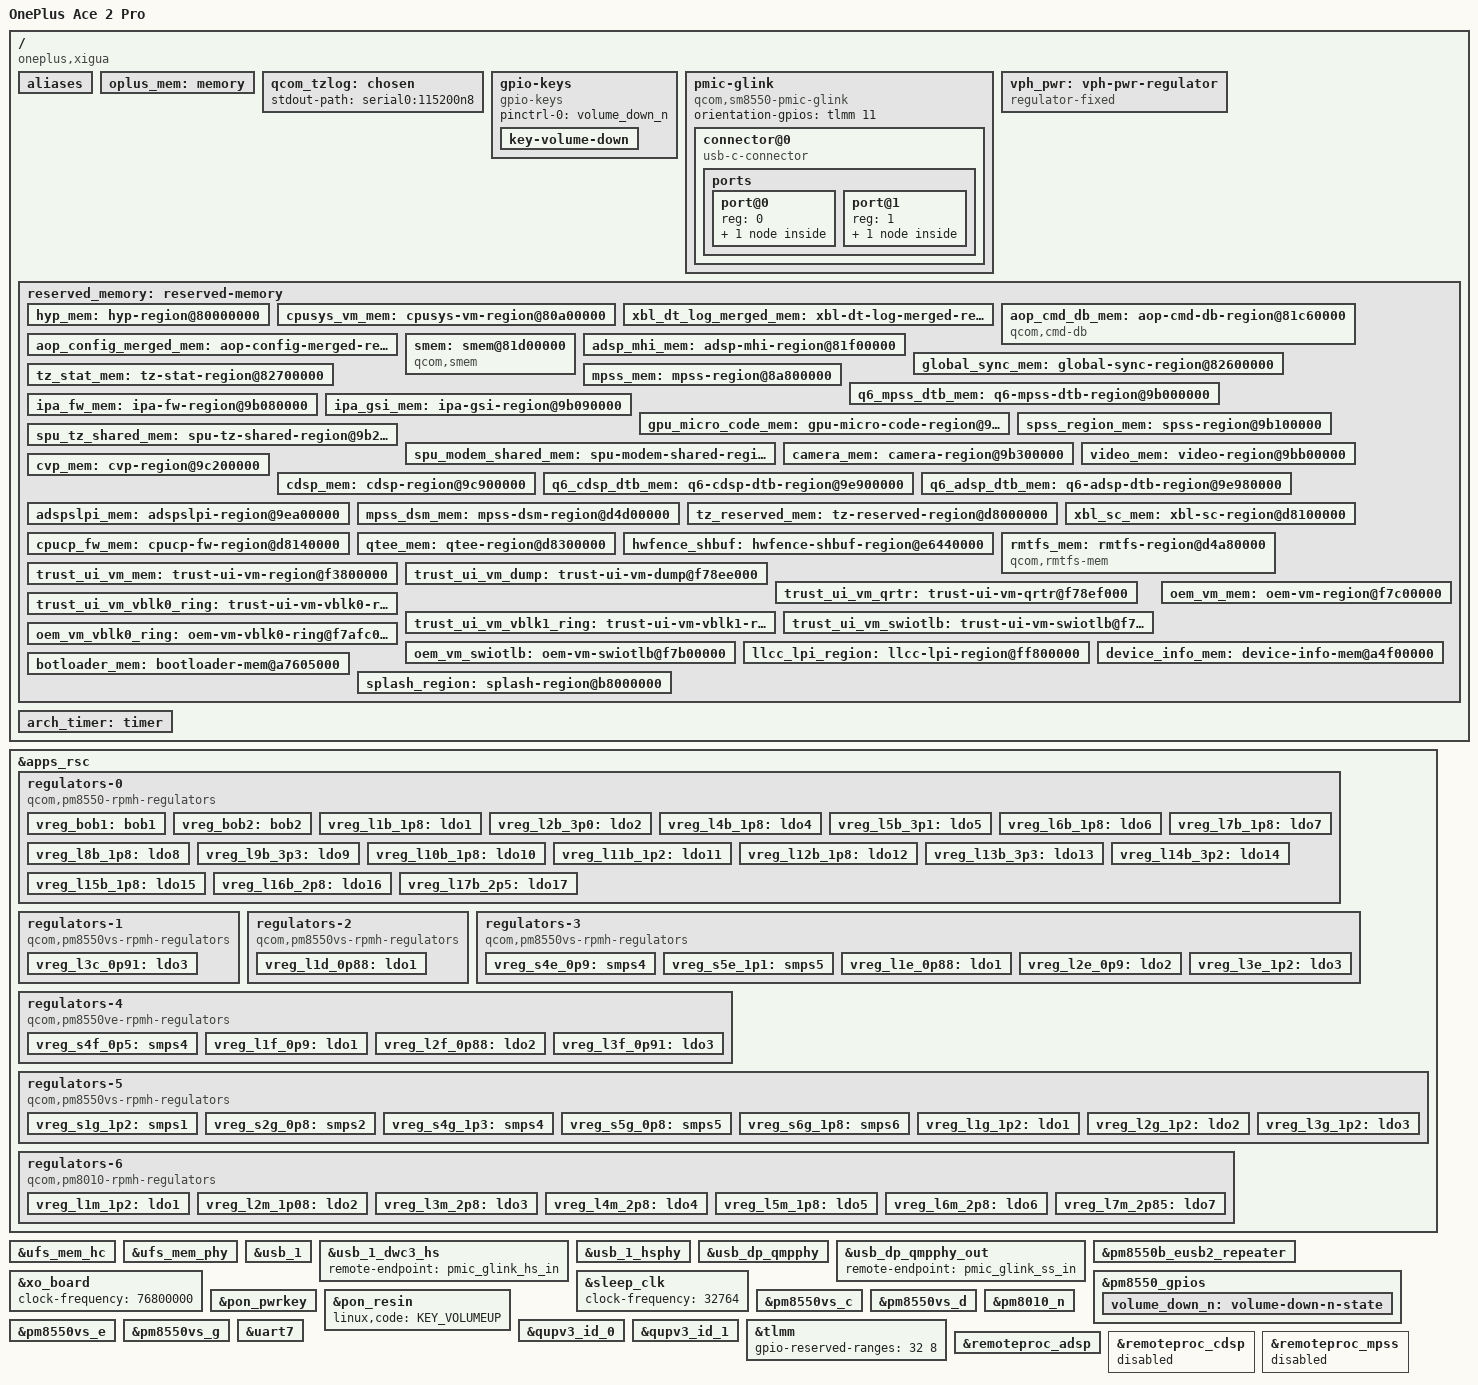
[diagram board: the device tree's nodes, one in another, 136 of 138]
// SPDX-License-Identifier: BSD-3-Clause
/*
 * OnePlus Ace 2 Pro (PJA110 / "xigua") - mainline bring-up, stage 0
 *
 * Goal of this revision: boot to a serial/USB shell. Deliberately minimal:
 * SoC + memory map + storage + USB + PMIC. No display, no touch, no modem.
 *
 * Sources for every board-specific value below:
 *   - reserved-memory : vendor_boot-A14.img (V14.0.0.701 / Android 14 base DTB)
 *   - regulators      : vendor base DTB, cross-checked against the sibling
 *                       OnePlus Ace 3 port (same PMIC set)
 *   - UFS / USB GPIOs : OnePlus sm8550 family layout (same as Ace 3)
 *   - RAM map         : see sm8550-oneplus-xigua_*.dts variants
 *
 * NOTE: the vendor base DTB keeps the factory memory map in an internal
 * "Kalama MTP,xigua" layout. We delete upstream's reserved-memory wholesale and
 * re-declare exactly what this device has (see docs/resmem-worklist.md).
 */

/dts-v1/;

#include <dt-bindings/arm/qcom,ids.h>
#include <dt-bindings/firmware/qcom,scm.h>
#include <dt-bindings/gpio/gpio.h>
#include <dt-bindings/input/input.h>
#include <dt-bindings/interrupt-controller/arm-gic.h>
#include <dt-bindings/leds/common.h>
#include <dt-bindings/regulator/qcom,rpmh-regulator.h>
#include <dt-bindings/sound/qcom,q6afe.h>
#include <dt-bindings/sound/qcom,q6asm.h>
#include <dt-bindings/sound/qcom,q6dsp-lpass-ports.h>
#include "sm8550.dtsi"
#include "pm8010.dtsi"
#include "pm8550.dtsi"
#include "pm8550b.dtsi"
#define PMK8550VE_SID 5
#include "pm8550ve.dtsi"
#include "pm8550vs.dtsi"
#include "pmk8550.dtsi"
#include "pmr735d_a.dtsi"

/*
 * Start from a clean slate: upstream sm8550.dtsi declares 47 reservations for
 * the reference boards. This device has 40, and 7 of the upstream ones do not
 * exist here at all. Re-declaring the node avoids a long, error-prone
 * /delete-node/ list (this is also what the Ace 3 port does).
 */
/delete-node/ &reserved_memory;

/ {
	model = "OnePlus Ace 2 Pro";
	compatible = "oneplus,xigua", "qcom,sm8550";
	chassis-type = "handset";

	/* same silicon variants as the rest of the OnePlus sm8550 family */
	qcom,msm-id = <0x207 0x20000 0x207 0x10000 0x218 0x20000 0x218 0x10000>;
	qcom,board-id = <0x10008 0>;

	aliases {
		serial0 = &uart7;
		serial1 = &uart14;
	};

	/*
	 * RAM map.
	 *
	 * Upstream sm8550.dtsi declares "memory@a0000000" with a zero size and
	 * expects the bootloader to fill it in; the vendor firmware does the same
	 * with its own /memory node. We cannot recover this device's real map from
	 * the firmware images (xbl/xbl_config/abl contain no size table, and the
	 * vendor base DTB leaves reg empty), so the map is supplied explicitly by
	 * the size specific variants, e.g. sm8550-oneplus-xigua-16G.dts.
	 *
	 * The base file keeps a single conservative window that is guaranteed to
	 * sit inside real RAM and outside every reserved region, so the base DTB
	 * boots (with less RAM) even without a variant.
	 */
	oplus_mem: memory {
		device_type = "memory";
		ddr_device_type = <0x08>;
		/* 0x80000000..0x8a800000: after hyp/cpusys/xbl, before mpss.
		 * Overridden by the size-specific variant. */
		reg = <0x00 0x80000000 0x00 0xa800000>;
	};

	/*
	 * ABL workaround -- see "ABL / DTBO" in docs/dts-build.md.
	 *
	 * This device's ABL refuses to apply a DTBO unless the *base* DTB contains
	 * a label named "qcom_tzlog" and a timer node labelled "arch_timer".
	 * Without them it drops to the bootloader menu.
	 *
	 * If we boot with `fastboot erase dtbo` (no overlay to apply) this is not
	 * needed -- but it costs nothing and makes an in-place DTBO setup work too,
	 * so we carry it. Upstream rejected putting this in sm8550.dtsi (it is an
	 * ABL quirk, not an SoC property), so it lives in the board DTS.
	 */
	qcom_tzlog: chosen {
		#address-cells = <2>;
		#size-cells = <2>;
		ranges;
		/* bring-up console: the vendor firmware disables it (console=ttynull) */
		stdout-path = "serial0:115200n8";
	};

	gpio-keys {
		compatible = "gpio-keys";
		pinctrl-names = "default";
		pinctrl-0 = <&volume_down_n>;

		key-volume-down {
			label = "Volume Down";
			linux,code = <KEY_VOLUMEDOWN>;
			gpios = <&pm8550_gpios 6 GPIO_ACTIVE_LOW>;
			debounce-interval = <15>;
			linux,can-disable;
			wakeup-source;
		};
	};

	pmic-glink {
		compatible = "qcom,sm8550-pmic-glink", "qcom,pmic-glink";
		#address-cells = <1>;
		#size-cells = <0>;
		orientation-gpios = <&tlmm 11 GPIO_ACTIVE_HIGH>;

		connector@0 {
			compatible = "usb-c-connector";
			reg = <0>;
			power-role = "dual";
			data-role = "dual";

			ports {
				#address-cells = <1>;
				#size-cells = <0>;

				port@0 {
					reg = <0>;

					pmic_glink_hs_in: endpoint {
						remote-endpoint = <&usb_1_dwc3_hs>;
					};
				};

				port@1 {
					reg = <1>;

					pmic_glink_ss_in: endpoint {
						remote-endpoint = <&usb_dp_qmpphy_out>;
					};
				};
			};
		};
	};

	vph_pwr: vph-pwr-regulator {
		compatible = "regulator-fixed";
		regulator-name = "vph_pwr";
		regulator-min-microvolt = <3700000>;
		regulator-max-microvolt = <3700000>;

		regulator-always-on;
		regulator-boot-on;
	};

	/*
	 * Memory map taken verbatim from the vendor base DTB (see
	 * docs/resmem-worklist.md for how each entry was derived).
	 */
	reserved_memory: reserved-memory {
		#address-cells = <2>;
		#size-cells = <2>;
		ranges;

		/* upstream calls this hyp_mem; the vendor node is gunyah_hyp_region */
		hyp_mem: hyp-region@80000000 {
			no-map;
			reg = <0x00 0x80000000 0x00 0xa00000>;
		};

		cpusys_vm_mem: cpusys-vm-region@80a00000 {
			no-map;
			reg = <0x00 0x80a00000 0x00 0x400000>;
		};

		/* NOTE: xigua has no hyp_tags_mem / hyp_tags_reserved_mem (upstream does) */

		/* merged xbl_dt_log, xbl_ramdump, aop_image */
		xbl_dt_log_merged_mem: xbl-dt-log-merged-region@81a00000 {
			no-map;
			reg = <0x00 0x81a00000 0x00 0x260000>;
		};

		aop_cmd_db_mem: aop-cmd-db-region@81c60000 {
			compatible = "qcom,cmd-db";
			no-map;
			reg = <0x00 0x81c60000 0x00 0x20000>;
		};

		/* merged aop_config, tme_crash_dump, tme_log, uefi_log */
		aop_config_merged_mem: aop-config-merged-region@81c80000 {
			no-map;
			reg = <0x00 0x81c80000 0x00 0x74000>;
		};

		smem: smem@81d00000 {
			compatible = "qcom,smem";
			no-map;
			reg = <0x00 0x81d00000 0x00 0x200000>;
			hwlocks = <&tcsr_mutex 3>;
		};

		adsp_mhi_mem: adsp-mhi-region@81f00000 {
			no-map;
			reg = <0x00 0x81f00000 0x00 0x20000>;
		};

		global_sync_mem: global-sync-region@82600000 {
			no-map;
			reg = <0x00 0x82600000 0x00 0x100000>;
		};

		tz_stat_mem: tz-stat-region@82700000 {
			no-map;
			reg = <0x00 0x82700000 0x00 0x100000>;
		};

		/* NOTE: xigua has no cdsp_secure_heap_mem (upstream has 70 MiB here) */

		mpss_mem: mpss-region@8a800000 {
			no-map;
			reg = <0x00 0x8a800000 0x00 0x10800000>;
		};

		q6_mpss_dtb_mem: q6-mpss-dtb-region@9b000000 {
			no-map;
			reg = <0x00 0x9b000000 0x00 0x80000>;
		};

		ipa_fw_mem: ipa-fw-region@9b080000 {
			no-map;
			reg = <0x00 0x9b080000 0x00 0x10000>;
		};

		ipa_gsi_mem: ipa-gsi-region@9b090000 {
			no-map;
			reg = <0x00 0x9b090000 0x00 0xa000>;
		};

		gpu_micro_code_mem: gpu-micro-code-region@9b09a000 {
			no-map;
			reg = <0x00 0x9b09a000 0x00 0x2000>;
		};

		spss_region_mem: spss-region@9b100000 {
			no-map;
			reg = <0x00 0x9b100000 0x00 0x180000>;
		};

		spu_tz_shared_mem: spu-tz-shared-region@9b280000 {
			no-map;
			reg = <0x00 0x9b280000 0x00 0x60000>;
		};

		spu_modem_shared_mem: spu-modem-shared-region@9b2e0000 {
			no-map;
			reg = <0x00 0x9b2e0000 0x00 0x20000>;
		};

		camera_mem: camera-region@9b300000 {
			no-map;
			reg = <0x00 0x9b300000 0x00 0x800000>;
		};

		video_mem: video-region@9bb00000 {
			no-map;
			reg = <0x00 0x9bb00000 0x00 0x700000>;
		};

		cvp_mem: cvp-region@9c200000 {
			no-map;
			reg = <0x00 0x9c200000 0x00 0x700000>;
		};

		cdsp_mem: cdsp-region@9c900000 {
			no-map;
			reg = <0x00 0x9c900000 0x00 0x2000000>;
		};

		q6_cdsp_dtb_mem: q6-cdsp-dtb-region@9e900000 {
			no-map;
			reg = <0x00 0x9e900000 0x00 0x80000>;
		};

		q6_adsp_dtb_mem: q6-adsp-dtb-region@9e980000 {
			no-map;
			reg = <0x00 0x9e980000 0x00 0x80000>;
		};

		/* xigua: 0x4880000 (72.5 MiB); upstream declares 0x4080000 */
		adspslpi_mem: adspslpi-region@9ea00000 {
			no-map;
			reg = <0x00 0x9ea00000 0x00 0x4880000>;
		};

		mpss_dsm_mem: mpss-dsm-region@d4d00000 {
			no-map;
			reg = <0x00 0xd4d00000 0x00 0x3300000>;
		};

		tz_reserved_mem: tz-reserved-region@d8000000 {
			no-map;
			reg = <0x00 0xd8000000 0x00 0x100000>;
		};

		xbl_sc_mem: xbl-sc-region@d8100000 {
			no-map;
			reg = <0x00 0xd8100000 0x00 0x40000>;
		};

		cpucp_fw_mem: cpucp-fw-region@d8140000 {
			no-map;
			reg = <0x00 0xd8140000 0x00 0x1c0000>;
		};

		qtee_mem: qtee-region@d8300000 {
			no-map;
			reg = <0x00 0xd8300000 0x00 0x500000>;
		};

		/* NOTE: xigua has no ta_mem (upstream: 138 MiB) and no tz_tags_mem */

		/*
		 * xigua: 0x279000. Upstream declares 0x279000 for the reference
		 * boards but the Ace 3 port needs 0x2dd000 -- so this value really is
		 * firmware-version dependent and must come from our own vendor DTB.
		 */
		hwfence_shbuf: hwfence-shbuf-region@e6440000 {
			no-map;
			reg = <0x00 0xe6440000 0x00 0x279000>;
		};

		/*
		 * The vendor firmware declares rmtfs through the QCOM-private
		 * "qcom,sharedmem-uio" binding with a zero base, so its real address
		 * is not directly readable. 0xd4a80000 is free on this device and
		 * 0xd4a80000 + 0x280000 == 0xd4d00000 (mpss_dsm start), so the
		 * upstream placement is correct here. See docs/resmem-worklist.md.
		 */
		rmtfs_mem: rmtfs-region@d4a80000 {
			compatible = "qcom,rmtfs-mem";
			reg = <0x00 0xd4a80000 0x00 0x280000>;
			no-map;

			qcom,client-id = <1>;
			qcom,vmid = <QCOM_SCM_VMID_MSS_MSA>;
		};

		/* trust_ui_vm / oem_vm live ~2 MiB lower than upstream */
		trust_ui_vm_mem: trust-ui-vm-region@f3800000 {
			no-map;
			reg = <0x00 0xf3800000 0x00 0x40ee000>;
		};

		trust_ui_vm_dump: trust-ui-vm-dump@f78ee000 {
			no-map;
			reg = <0x00 0xf78ee000 0x00 0x1000>;
		};

		trust_ui_vm_qrtr: trust-ui-vm-qrtr@f78ef000 {
			no-map;
			reg = <0x00 0xf78ef000 0x00 0x9000>;
		};

		trust_ui_vm_vblk0_ring: trust-ui-vm-vblk0-ring@f78f8000 {
			no-map;
			reg = <0x00 0xf78f8000 0x00 0x4000>;
		};

		trust_ui_vm_vblk1_ring: trust-ui-vm-vblk1-ring@f78fc000 {
			no-map;
			reg = <0x00 0xf78fc000 0x00 0x4000>;
		};

		trust_ui_vm_swiotlb: trust-ui-vm-swiotlb@f7900000 {
			no-map;
			reg = <0x00 0xf7900000 0x00 0x100000>;
		};

		oem_vm_vblk0_ring: oem-vm-vblk0-ring@f7afc000 {
			no-map;
			reg = <0x00 0xf7afc000 0x00 0x4000>;
		};

		oem_vm_swiotlb: oem-vm-swiotlb@f7b00000 {
			no-map;
			reg = <0x00 0xf7b00000 0x00 0x100000>;
		};

		oem_vm_mem: oem-vm-region@f7c00000 {
			no-map;
			reg = <0x00 0xf7c00000 0x00 0x4800000>;
		};

		/* xigua-only: no upstream equivalent */
		llcc_lpi_region: llcc-lpi-region@ff800000 {
			no-map;
			reg = <0x00 0xff800000 0x00 0x600000>;
		};

		/*
		 * The following three were found on the LIVE device tree
		 * (/sys/firmware/fdt) but are absent from the OTA firmware images we
		 * analysed -- the vendor base DTB in vendor_boot does not carry them.
		 * They are real reservations made by this unit's bootloader, so we
		 * reproduce them.
		 */
		device_info_mem: device-info-mem@a4f00000 {
			no-map;
			reg = <0x00 0xa4f00000 0x00 0x8000>;
		};

		botloader_mem: bootloader-mem@a7605000 {
			no-map;
			reg = <0x00 0xa7605000 0x00 0x8000>;
		};

		/* 43 MiB splash/framebuffer reservation */
		splash_region: splash-region@b8000000 {
			no-map;
			reg = <0x00 0xb8000000 0x00 0x2b00000>;
		};
	};
};

/* ---- regulators: identical PMIC set to the sibling Ace 3 -------------- */

&apps_rsc {
	regulators-0 {
		compatible = "qcom,pm8550-rpmh-regulators";
		qcom,pmic-id = "b";

		vdd-bob1-supply = <&vph_pwr>;
		vdd-bob2-supply = <&vph_pwr>;
		vdd-l1-l4-l10-supply = <&vreg_s6g_1p8>;
		vdd-l2-l13-l14-supply = <&vreg_bob1>;
		vdd-l3-supply = <&vreg_s4g_1p3>;
		vdd-l5-l16-supply = <&vreg_bob1>;
		vdd-l6-l7-supply = <&vreg_bob1>;
		vdd-l8-l9-supply = <&vreg_bob1>;
		vdd-l11-supply = <&vreg_s4g_1p3>;
		vdd-l12-supply = <&vreg_s6g_1p8>;
		vdd-l15-supply = <&vreg_s6g_1p8>;
		vdd-l17-supply = <&vreg_bob2>;

		vreg_bob1: bob1 {
			regulator-name = "vreg_bob1";
			regulator-min-microvolt = <3296000>;
			regulator-max-microvolt = <3960000>;
			regulator-initial-mode = <RPMH_REGULATOR_MODE_HPM>;
		};

		vreg_bob2: bob2 {
			regulator-name = "vreg_bob2";
			regulator-min-microvolt = <2720000>;
			regulator-max-microvolt = <3960000>;
			regulator-initial-mode = <RPMH_REGULATOR_MODE_HPM>;
		};

		vreg_l1b_1p8: ldo1 {
			regulator-name = "vreg_l1b_1p8";
			regulator-min-microvolt = <1800000>;
			regulator-max-microvolt = <1800000>;
			regulator-initial-mode = <RPMH_REGULATOR_MODE_HPM>;
		};

		vreg_l2b_3p0: ldo2 {
			regulator-name = "vreg_l2b_3p0";
			regulator-min-microvolt = <3008000>;
			regulator-max-microvolt = <3008000>;
			regulator-initial-mode = <RPMH_REGULATOR_MODE_HPM>;
		};

		vreg_l4b_1p8: ldo4 {
			regulator-name = "vreg_l4b_1p8";
			regulator-min-microvolt = <1800000>;
			regulator-max-microvolt = <2960000>;
			regulator-initial-mode = <RPMH_REGULATOR_MODE_HPM>;
		};

		vreg_l5b_3p1: ldo5 {
			regulator-name = "vreg_l5b_3p1";
			regulator-min-microvolt = <3104000>;
			regulator-max-microvolt = <3104000>;
			regulator-initial-mode = <RPMH_REGULATOR_MODE_HPM>;
		};

		vreg_l6b_1p8: ldo6 {
			regulator-name = "vreg_l6b_1p8";
			regulator-min-microvolt = <1800000>;
			regulator-max-microvolt = <3008000>;
			regulator-initial-mode = <RPMH_REGULATOR_MODE_HPM>;
		};

		vreg_l7b_1p8: ldo7 {
			regulator-name = "vreg_l7b_1p8";
			regulator-min-microvolt = <1800000>;
			regulator-max-microvolt = <3008000>;
			regulator-initial-mode = <RPMH_REGULATOR_MODE_HPM>;
		};

		vreg_l8b_1p8: ldo8 {
			regulator-name = "vreg_l8b_1p8";
			regulator-min-microvolt = <1800000>;
			regulator-max-microvolt = <3008000>;
			regulator-initial-mode = <RPMH_REGULATOR_MODE_HPM>;
		};

		vreg_l9b_3p3: ldo9 {
			regulator-name = "vreg_l9b_3p3";
			regulator-min-microvolt = <2960000>;
			regulator-max-microvolt = <3304000>;
			regulator-initial-mode = <RPMH_REGULATOR_MODE_HPM>;
		};

		vreg_l10b_1p8: ldo10 {
			regulator-name = "vreg_l10b_1p8";
			regulator-min-microvolt = <1800000>;
			regulator-max-microvolt = <1800000>;
			regulator-initial-mode = <RPMH_REGULATOR_MODE_HPM>;
		};

		vreg_l11b_1p2: ldo11 {
			regulator-name = "vreg_l11b_1p2";
			regulator-min-microvolt = <1200000>;
			regulator-max-microvolt = <1504000>;
			regulator-initial-mode = <RPMH_REGULATOR_MODE_HPM>;
		};

		vreg_l12b_1p8: ldo12 {
			regulator-name = "vreg_l12b_1p8";
			regulator-min-microvolt = <1800000>;
			regulator-max-microvolt = <1800000>;
			regulator-initial-mode = <RPMH_REGULATOR_MODE_HPM>;
		};

		vreg_l13b_3p3: ldo13 {
			regulator-name = "vreg_l13b_3p3";
			regulator-min-microvolt = <3000000>;
			regulator-max-microvolt = <3304000>;
			regulator-initial-mode = <RPMH_REGULATOR_MODE_HPM>;
		};

		vreg_l14b_3p2: ldo14 {
			regulator-name = "vreg_l14b_3p2";
			regulator-min-microvolt = <3200000>;
			regulator-max-microvolt = <3200000>;
			regulator-initial-mode = <RPMH_REGULATOR_MODE_HPM>;
		};

		vreg_l15b_1p8: ldo15 {
			regulator-name = "vreg_l15b_1p8";
			regulator-min-microvolt = <1800000>;
			regulator-max-microvolt = <1800000>;
			regulator-initial-mode = <RPMH_REGULATOR_MODE_HPM>;
		};

		vreg_l16b_2p8: ldo16 {
			regulator-name = "vreg_l16b_2p8";
			regulator-min-microvolt = <2800000>;
			regulator-max-microvolt = <2800000>;
			regulator-initial-mode = <RPMH_REGULATOR_MODE_HPM>;
		};

		vreg_l17b_2p5: ldo17 {
			regulator-name = "vreg_l17b_2p5";
			regulator-min-microvolt = <2504000>;
			regulator-max-microvolt = <2504000>;
			regulator-initial-mode = <RPMH_REGULATOR_MODE_HPM>;
		};
	};

	regulators-1 {
		compatible = "qcom,pm8550vs-rpmh-regulators";
		qcom,pmic-id = "c";

		vdd-l3-supply = <&vreg_s4e_0p9>;

		vreg_l3c_0p91: ldo3 {
			regulator-name = "vreg_l3c_0p91";
			regulator-min-microvolt = <880000>;
			regulator-max-microvolt = <912000>;
			regulator-initial-mode = <RPMH_REGULATOR_MODE_HPM>;
		};
	};

	regulators-2 {
		compatible = "qcom,pm8550vs-rpmh-regulators";
		qcom,pmic-id = "d";

		vdd-l1-supply = <&vreg_s4e_0p9>;

		vreg_l1d_0p88: ldo1 {
			regulator-name = "vreg_l1d_0p88";
			regulator-min-microvolt = <880000>;
			regulator-max-microvolt = <920000>;
			regulator-initial-mode = <RPMH_REGULATOR_MODE_HPM>;
		};
	};

	regulators-3 {
		compatible = "qcom,pm8550vs-rpmh-regulators";
		qcom,pmic-id = "e";

		vdd-l1-supply = <&vreg_s4e_0p9>;
		vdd-l2-supply = <&vreg_s4e_0p9>;
		vdd-l3-supply = <&vreg_s4g_1p3>;
		vdd-s4-supply = <&vph_pwr>;
		vdd-s5-supply = <&vph_pwr>;

		vreg_s4e_0p9: smps4 {
			regulator-name = "vreg_s4e_0p9";
			regulator-min-microvolt = <904000>;
			regulator-max-microvolt = <984000>;
			regulator-initial-mode = <RPMH_REGULATOR_MODE_HPM>;
		};

		vreg_s5e_1p1: smps5 {
			regulator-name = "vreg_s5e_1p1";
			regulator-min-microvolt = <1080000>;
			regulator-max-microvolt = <1120000>;
			regulator-initial-mode = <RPMH_REGULATOR_MODE_HPM>;
		};

		vreg_l1e_0p88: ldo1 {
			regulator-name = "vreg_l1e_0p88";
			regulator-min-microvolt = <880000>;
			regulator-max-microvolt = <880000>;
			regulator-initial-mode = <RPMH_REGULATOR_MODE_HPM>;
		};

		vreg_l2e_0p9: ldo2 {
			regulator-name = "vreg_l2e_0p9";
			regulator-min-microvolt = <904000>;
			regulator-max-microvolt = <970000>;
			regulator-initial-mode = <RPMH_REGULATOR_MODE_HPM>;
		};

		vreg_l3e_1p2: ldo3 {
			regulator-name = "vreg_l3e_1p2";
			regulator-min-microvolt = <1200000>;
			regulator-max-microvolt = <1200000>;
			regulator-initial-mode = <RPMH_REGULATOR_MODE_HPM>;
		};
	};

	regulators-4 {
		compatible = "qcom,pm8550ve-rpmh-regulators";
		qcom,pmic-id = "f";

		vdd-l1-supply = <&vreg_s4e_0p9>;
		vdd-l2-supply = <&vreg_s4e_0p9>;
		vdd-l3-supply = <&vreg_s4e_0p9>;
		vdd-s4-supply = <&vph_pwr>;

		vreg_s4f_0p5: smps4 {
			regulator-name = "vreg_s4f_0p5";
			regulator-min-microvolt = <500000>;
			regulator-max-microvolt = <700000>;
			regulator-initial-mode = <RPMH_REGULATOR_MODE_HPM>;
		};

		vreg_l1f_0p9: ldo1 {
			regulator-name = "vreg_l1f_0p9";
			regulator-min-microvolt = <912000>;
			regulator-max-microvolt = <912000>;
			regulator-initial-mode = <RPMH_REGULATOR_MODE_HPM>;
		};

		vreg_l2f_0p88: ldo2 {
			regulator-name = "vreg_l2f_0p88";
			regulator-min-microvolt = <880000>;
			regulator-max-microvolt = <912000>;
			regulator-initial-mode = <RPMH_REGULATOR_MODE_HPM>;
		};

		vreg_l3f_0p91: ldo3 {
			regulator-name = "vreg_l3f_0p91";
			regulator-min-microvolt = <880000>;
			regulator-max-microvolt = <912000>;
			regulator-initial-mode = <RPMH_REGULATOR_MODE_HPM>;
		};
	};

	regulators-5 {
		compatible = "qcom,pm8550vs-rpmh-regulators";
		qcom,pmic-id = "g";

		vdd-l1-supply = <&vreg_s4g_1p3>;
		vdd-l2-supply = <&vreg_s4g_1p3>;
		vdd-l3-supply = <&vreg_s4g_1p3>;
		vdd-s1-supply = <&vph_pwr>;
		vdd-s2-supply = <&vph_pwr>;
		vdd-s3-supply = <&vph_pwr>;
		vdd-s4-supply = <&vph_pwr>;
		vdd-s5-supply = <&vph_pwr>;
		vdd-s6-supply = <&vph_pwr>;

		vreg_s1g_1p2: smps1 {
			regulator-name = "vreg_s1g_1p2";
			regulator-min-microvolt = <1200000>;
			regulator-max-microvolt = <1300000>;
			regulator-initial-mode = <RPMH_REGULATOR_MODE_HPM>;
		};

		vreg_s2g_0p8: smps2 {
			regulator-name = "vreg_s2g_0p8";
			regulator-min-microvolt = <800000>;
			regulator-max-microvolt = <1000000>;
			regulator-initial-mode = <RPMH_REGULATOR_MODE_HPM>;
		};

		vreg_s4g_1p3: smps4 {
			regulator-name = "vreg_s4g_1p3";
			regulator-min-microvolt = <1200000>;
			regulator-max-microvolt = <1352000>;
			regulator-initial-mode = <RPMH_REGULATOR_MODE_HPM>;
		};

		vreg_s5g_0p8: smps5 {
			regulator-name = "vreg_s5g_0p8";
			regulator-min-microvolt = <500000>;
			regulator-max-microvolt = <1004000>;
			regulator-initial-mode = <RPMH_REGULATOR_MODE_HPM>;
		};

		vreg_s6g_1p8: smps6 {
			regulator-name = "vreg_s6g_1p8";
			regulator-min-microvolt = <1800000>;
			regulator-max-microvolt = <2000000>;
			regulator-initial-mode = <RPMH_REGULATOR_MODE_HPM>;
		};

		vreg_l1g_1p2: ldo1 {
			regulator-name = "vreg_l1g_1p2";
			regulator-min-microvolt = <1200000>;
			regulator-max-microvolt = <1200000>;
			regulator-initial-mode = <RPMH_REGULATOR_MODE_HPM>;
		};

		vreg_l2g_1p2: ldo2 {
			regulator-name = "vreg_l2g_1p2";
			regulator-min-microvolt = <1200000>;
			regulator-max-microvolt = <1200000>;
			regulator-initial-mode = <RPMH_REGULATOR_MODE_HPM>;
		};

		vreg_l3g_1p2: ldo3 {
			regulator-name = "vreg_l3g_1p2";
			regulator-min-microvolt = <1200000>;
			regulator-max-microvolt = <1200000>;
			regulator-initial-mode = <RPMH_REGULATOR_MODE_HPM>;
		};
	};

	regulators-6 {
		compatible = "qcom,pm8010-rpmh-regulators";
		qcom,pmic-id = "m";

		vdd-l1-l2-supply = <&vreg_s4g_1p3>;
		vdd-l3-l4-supply = <&vreg_bob2>;
		vdd-l5-supply = <&vreg_s6g_1p8>;
		vdd-l6-supply = <&vreg_s6g_1p8>;
		vdd-l7-supply = <&vreg_bob1>;

		vreg_l1m_1p2: ldo1 {
			regulator-name = "vreg_l1m_1p2";
			regulator-min-microvolt = <1200000>;
			regulator-max-microvolt = <1200000>;
			regulator-initial-mode = <RPMH_REGULATOR_MODE_HPM>;
		};

		vreg_l2m_1p08: ldo2 {
			regulator-name = "vreg_l2m_1p08";
			regulator-min-microvolt = <1056000>;
			regulator-max-microvolt = <1104000>;
			regulator-initial-mode = <RPMH_REGULATOR_MODE_HPM>;
		};

		vreg_l3m_2p8: ldo3 {
			regulator-name = "vreg_l3m_2p8";
			regulator-min-microvolt = <2800000>;
			regulator-max-microvolt = <2800000>;
			regulator-initial-mode = <RPMH_REGULATOR_MODE_HPM>;
		};

		vreg_l4m_2p8: ldo4 {
			regulator-name = "vreg_l4m_2p8";
			regulator-min-microvolt = <2800000>;
			regulator-max-microvolt = <2800000>;
			regulator-initial-mode = <RPMH_REGULATOR_MODE_HPM>;
		};

		vreg_l5m_1p8: ldo5 {
			regulator-name = "vreg_l5m_1p8";
			regulator-min-microvolt = <1800000>;
			regulator-max-microvolt = <1800000>;
			regulator-initial-mode = <RPMH_REGULATOR_MODE_HPM>;
		};

		vreg_l6m_2p8: ldo6 {
			regulator-name = "vreg_l6m_2p8";
			regulator-min-microvolt = <2800000>;
			regulator-max-microvolt = <2800000>;
			regulator-initial-mode = <RPMH_REGULATOR_MODE_HPM>;
		};

		vreg_l7m_2p85: ldo7 {
			regulator-name = "vreg_l7m_2p85";
			regulator-min-microvolt = <2800000>;
			regulator-max-microvolt = <2904000>;
			regulator-initial-mode = <RPMH_REGULATOR_MODE_HPM>;
		};
	};
};

/* ---- storage ---------------------------------------------------------- */

&ufs_mem_hc {
	reset-gpios = <&tlmm 210 GPIO_ACTIVE_LOW>;
	vcc-supply = <&vreg_l17b_2p5>;
	vcc-max-microamp = <1300000>;
	vccq-supply = <&vreg_l1g_1p2>;
	vccq-max-microamp = <1200000>;
	vdd-hba-supply = <&vreg_l3g_1p2>;

	status = "okay";
};

&ufs_mem_phy {
	vdda-phy-supply = <&vreg_l1d_0p88>;
	vdda-pll-supply = <&vreg_l3e_1p2>;

	status = "okay";
};

/* ---- USB (bring-up shell over USB networking) ------------------------- */

&usb_1 {
	status = "okay";
};

&usb_1_dwc3_hs {
	remote-endpoint = <&pmic_glink_hs_in>;
};

&usb_1_hsphy {
	vdd-supply = <&vreg_l1e_0p88>;
	vdda12-supply = <&vreg_l3e_1p2>;

	phys = <&pm8550b_eusb2_repeater>;
	status = "okay";
};

&usb_dp_qmpphy {
	vdda-phy-supply = <&vreg_l3e_1p2>;
	vdda-pll-supply = <&vreg_l3f_0p91>;

	status = "okay";
};

&usb_dp_qmpphy_out {
	remote-endpoint = <&pmic_glink_ss_in>;
};

&pm8550b_eusb2_repeater {
	vdd18-supply = <&vreg_l15b_1p8>;
	vdd3-supply = <&vreg_l5b_3p1>;
};

/* ---- clocks, keys, PMIC glue ----------------------------------------- */

/*
 * Second half of the ABL workaround: ABL requires the timer node to carry the
 * label "arch_timer". Upstream sm8550.dtsi declares it as a bare "timer" node
 * with no label, so we re-open it here to attach one. No properties change.
 */
/ {
	arch_timer: timer {
	};
};

&xo_board {
	clock-frequency = <76800000>;
};

&sleep_clk {
	clock-frequency = <32764>;
};

&pm8550_gpios {
	volume_down_n: volume-down-n-state {
		pins = "gpio6";
		function = "normal";
		power-source = <1>;
		bias-pull-up;
		input-enable;
	};
};

&pon_pwrkey {
	status = "okay";
};

&pon_resin {
	status = "okay";
	linux,code = <KEY_VOLUMEUP>;
};

&pm8550vs_c {
	status = "okay";
};

&pm8550vs_d {
	status = "okay";
};

&pm8550vs_e {
	status = "okay";
};

&pm8550vs_g {
	status = "okay";
};

&pm8010_n {
	status = "okay";
};

&qupv3_id_0 {
	status = "okay";
};

&qupv3_id_1 {
	status = "okay";
};

/* bring-up console (matches the vendor "serial0" alias) */
&uart7 {
	status = "okay";
};

&tlmm {
	gpio-reserved-ranges = <32 8>;
};

/* ADSP charger/PMIC-GLINK firmware is shipped by firmware-oneplus-xigua-adsp. */

&remoteproc_adsp {
	firmware-name = "qcom/sm8550/xigua/adsp.mbn",
			"qcom/sm8550/xigua/adsp_dtb.mbn";
	status = "okay";
};

&remoteproc_cdsp {
	status = "disabled";
};

&remoteproc_mpss {
	status = "disabled";
};
